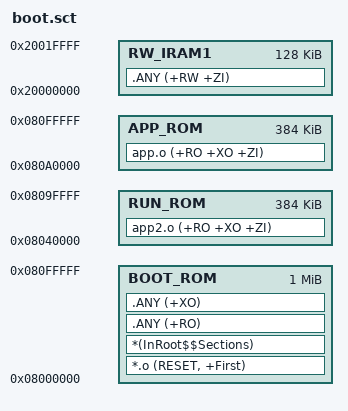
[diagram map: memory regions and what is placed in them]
; *************************************************************
; *** Scatter-Loading Description File generated by uVision ***
; *************************************************************

BOOT_ROM 0x08000000 0x00100000  {    ; load region size_region
  BOOT_ROM 0x08000000 0x00100000  {  ; load address = execution address
   *.o (RESET, +First)
   *(InRoot$$Sections)
   .ANY (+RO)
   .ANY (+XO)
  }
  RW_IRAM1 0x20000000 0x00020000  {  ; RW data
   .ANY (+RW +ZI)
  }
}

RUN_ROM 0x08040000 0x00060000  {
  RUN_ROM 0x08040000 0x00060000  {  ; load address = execution address
   app2.o (+RO +XO +ZI)
  }
}

APP_ROM 0x080A0000 0x00060000  {
  APP_ROM 0x080A0000 0x00060000  {  ; load address = execution address
   app.o (+RO +XO +ZI)
  }
}
